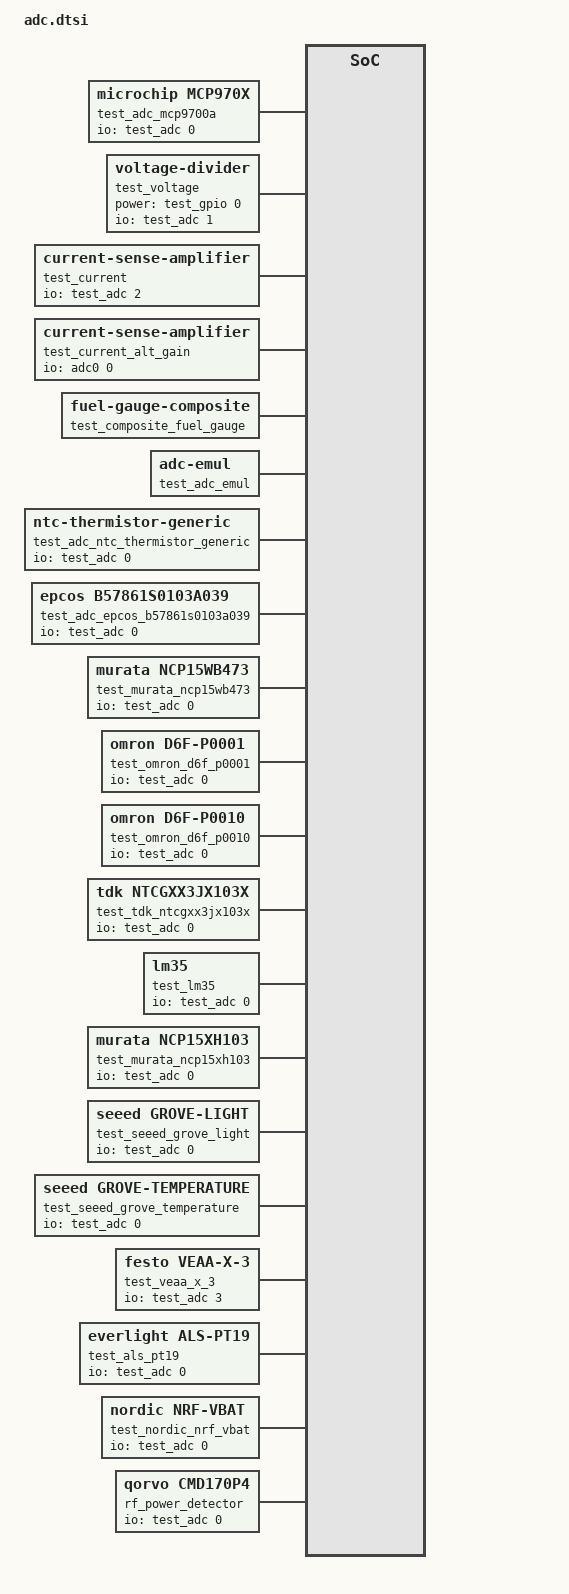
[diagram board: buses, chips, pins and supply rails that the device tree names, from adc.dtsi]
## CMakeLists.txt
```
# SPDX-License-Identifier: Apache-2.0

cmake_minimum_required(VERSION 3.28.0)
find_package(Zephyr REQUIRED HINTS $ENV{ZEPHYR_BASE})
project(build_all)

# Exclude main when running the generic test because ztest supplies its own
target_sources_ifndef(CONFIG_GENERIC_SENSOR_TEST app PRIVATE src/main.c)
target_sources_ifdef(CONFIG_GENERIC_SENSOR_TEST app PRIVATE src/generic_test.c)
```

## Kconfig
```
# Copyright (c) 2023 Google LLC
# SPDX-License-Identifier: Apache-2.0

config GENERIC_SENSOR_TEST
	bool "Compile and run the generic sensor tests"
	depends on ZTEST
	help
	  Enables building and running the generic sensor test suite that will
	  iterate through the device tree and run sample path tests on any
	  sensor that supports the backend sensor emulator API.

config GENERIC_SENSOR_TEST_NUM_EXPECTED_VALS
	int "Number of expected values to use in test"
	default 5
	depends on GENERIC_SENSOR_TEST
	help
	  Controls the number of expected values to use in the generic sensor
	  test, interpolated from the sensor's reported lower and upper sample
	  range boundaries. The test will run one iteration for each expected
	  value. For example, if GENERIC_TEST_NUM_EXPECTED_VALS == 5, and the
	  sensor range is 0..100, the test will run 5 times with expected values
	  0, 25, 50, 75, and 100. These iterations are run in parallel.

source "Kconfig.zephyr"
```

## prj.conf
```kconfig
# zephyr-keep-sorted-start
CONFIG_ADC=y
CONFIG_DAC=y
CONFIG_DHT20_CRC=y
CONFIG_EMUL=y
CONFIG_FUEL_GAUGE=y
CONFIG_GPIO=y
CONFIG_I2C=y
CONFIG_I3C=y
CONFIG_ICM42605_TRIGGER_NONE=y
CONFIG_ICM566XX_TRIGGER_NONE=y
CONFIG_LOG=y
CONFIG_MFD=y
CONFIG_MODBUS=y
CONFIG_MODBUS_RAW_ADU=y
CONFIG_PWM=y
CONFIG_PWM_CAPTURE=y
CONFIG_SENSOR=y
CONFIG_SENSOR_LOG_LEVEL_DBG=y
CONFIG_SERIAL=y
CONFIG_SMBUS=y
CONFIG_SPI=y
CONFIG_SYS_CLOCK_TICKS_PER_SEC=1000
CONFIG_TEST=y
CONFIG_TEST_USERSPACE=y
CONFIG_W1=y
# zephyr-keep-sorted-stop
```

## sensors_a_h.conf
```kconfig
CONFIG_TEST=y
CONFIG_SYS_CLOCK_TICKS_PER_SEC=1000
CONFIG_GPIO=y
CONFIG_I2C=y
CONFIG_SENSOR=y
CONFIG_SPI=y
CONFIG_LOG=y
CONFIG_SENSOR_LOG_LEVEL_DBG=y
CONFIG_TEST_USERSPACE=y
CONFIG_ADC=y
CONFIG_ADT7420=y
CONFIG_ADXL362=y
CONFIG_ADXL372=y
CONFIG_AK8975=y
CONFIG_AMG88XX=y
CONFIG_AMS_IAQ_CORE=y
CONFIG_APDS9960=y
CONFIG_BMA280=y
CONFIG_BMC150_MAGN=y
CONFIG_BME280=y
CONFIG_BMG160=y
CONFIG_BMI160=y
CONFIG_BMI270=y
CONFIG_BMM150=y
CONFIG_BMP388=y
CONFIG_BQ274XX=y
CONFIG_CCS811=y
CONFIG_DHT=y
CONFIG_DPS310=y
CONFIG_ENS210=y
CONFIG_FDC2X1X=y
CONFIG_FXAS21002=y
CONFIG_FXOS8700=y
CONFIG_HMC5883L=y
CONFIG_HP206C=y
CONFIG_HTS221=y
CONFIG_ADXL345=y
CONFIG_MPR=y
```

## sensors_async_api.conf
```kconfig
CONFIG_SENSOR_ASYNC_API=y
CONFIG_ADXL345_STREAM=y
CONFIG_ADXL355_STREAM=y
CONFIG_ADXL362_STREAM=y
CONFIG_ADXL367_STREAM=y
CONFIG_ADXL372_STREAM=y
CONFIG_BMA4XX_STREAM=y
CONFIG_BMM350_STREAM=y
CONFIG_PAA3905_STREAM=y
CONFIG_PAT9136_STREAM=y
CONFIG_RM3100_STREAM=y
CONFIG_IIS3DWB_STREAM=y
CONFIG_LSM6DSV16X_STREAM=y
CONFIG_ICM45686_STREAM=y
CONFIG_ICM4268X_STREAM=y
CONFIG_BMI08X_GYRO_STREAM=y
CONFIG_BMI08X_ACCEL_STREAM=y
CONFIG_MAX30009_STREAM=y
```

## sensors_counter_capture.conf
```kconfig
# Copyright (c) 2026 Meta Platforms
# SPDX-License-Identifier: Apache-2.0

CONFIG_COUNTER_CAPTURE=y
CONFIG_LSM6DSV16X_TRIGGER_GLOBAL_THREAD=y
```

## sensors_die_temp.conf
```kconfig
# zephyr-keep-sorted-start
CONFIG_IIS2ICLX_ENABLE_TEMP=y
CONFIG_IIS3DWB_ENABLE_TEMP=y
CONFIG_ISM330DHCX_ENABLE_TEMP=y
CONFIG_LIS2DE12_ENABLE_TEMP=y
CONFIG_LIS2DS12_ENABLE_TEMP=y
CONFIG_LIS2DUX12_ENABLE_TEMP=y
CONFIG_LSM6DS0_ENABLE_TEMP=y
CONFIG_LSM6DSL_ENABLE_TEMP=y
CONFIG_LSM6DSO16IS_ENABLE_TEMP=y
CONFIG_LSM6DSO_ENABLE_TEMP=y
CONFIG_LSM6DSV16X_ENABLE_TEMP=y
# zephyr-keep-sorted-stop
```

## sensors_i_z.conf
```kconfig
CONFIG_TEST=y
CONFIG_TEST_USERSPACE=y
CONFIG_GPIO=y
CONFIG_I2C=y
CONFIG_SENSOR=y
CONFIG_SPI=y
CONFIG_LOG=y
CONFIG_SENSOR_LOG_LEVEL_DBG=y
CONFIG_ICM42605=y
CONFIG_ICM42605_TRIGGER_OWN_THREAD=y
CONFIG_IIS3DHHC=y
CONFIG_ISL29035=y
CONFIG_LIS2DH=y
CONFIG_LIS2DS12=y
CONFIG_LIS2MDL=y
CONFIG_LIS3MDL=y
CONFIG_LPS22HB=y
CONFIG_LPS22HH=y
CONFIG_LPS25HB=y
CONFIG_LSM303DLHC_MAGN=y
CONFIG_LSM6DS0=y
CONFIG_LSM6DSL=y
CONFIG_LSM6DSO=y
CONFIG_LSM9DS0_GYRO=y
CONFIG_LSM9DS0_MFD=y
CONFIG_MAX30101=y
CONFIG_MAX44009=y
CONFIG_MAX17055=y
CONFIG_MAX1726X=y
CONFIG_MAX6675=y
CONFIG_MCP9808=y
CONFIG_MPU6050=y
CONFIG_MS5607=y
CONFIG_OPT3001=y
CONFIG_SHT3XD=y
CONFIG_SI7006=y
CONFIG_SI7055=y
CONFIG_SI7060=y
CONFIG_SM351LT=y
CONFIG_STM32_TEMP=y
CONFIG_SX9500=y
CONFIG_TACH_NPCX=y
CONFIG_TEMP_NRF5=y
CONFIG_SBS_GAUGE=y
CONFIG_TH02=y
CONFIG_TI_HDC=y
CONFIG_TMP007=y
CONFIG_TMP112=y
CONFIG_TMP116=y
CONFIG_VL53L0X=y
```

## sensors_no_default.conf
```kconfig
# zephyr-keep-sorted-start
CONFIG_BMC150_MAGN_TRIGGER=y
CONFIG_BMC150_MAGN_TRIGGER_DRDY=y
CONFIG_BMM150_TRIGGER_DIRECT=y
CONFIG_BMP388_TRIGGER_DIRECT=y
CONFIG_LM77_TRIGGER=y
CONFIG_LSM9DS0_GYRO_TRIGGERS=y
CONFIG_LSM9DS0_GYRO_TRIGGER_DRDY=y
CONFIG_TMAG5170_TRIGGER_DIRECT=y
CONFIG_VL53L1X_INTERRUPT_MODE=n
CONFIG_VL53L1X_XSHUT=n
# zephyr-keep-sorted-stop
```

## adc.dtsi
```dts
/*
 * Copyright (c) 2023 FTP Technologies
 * Copyright (c) 2023, Google LLC
 *
 * SPDX-License-Identifier: Apache-2.0
 *
 * Application overlay for ADC devices
 */

#include <zephyr/dt-bindings/battery/battery.h>

test_adc_mcp9700a: mcp9700a {
	status = "okay";
	compatible = "microchip,mcp970x";
	family = "MCP9700/9700A";
	io-channels = <&test_adc 0>;
};

test_voltage: voltage {
	status = "okay";
	compatible = "voltage-divider";
	io-channels = <&test_adc 1>;
	io-channel-names = "VOLTAGE";
	output-ohms = <47000>; /* R1 */
	full-ohms = <(100000 + 47000)>; /* R2 + R1 */
	power-gpios = <&test_gpio 0 0>;
};

test_current: current_amp {
	status = "okay";
	compatible = "current-sense-amplifier";
	io-channels = <&test_adc 2>;
	io-channel-names = "CURRENT_AMP";
	sense-resistor-milli-ohms = <1>;
	sense-gain-mult = <1>;
	sense-gain-div = <1>;
	zero-current-voltage-mv = <0>;
};

test_current_alt_gain: current_amp_alt_gain {
	compatible = "current-sense-amplifier";
	io-channels = <&adc0 0>;
	sense-resistor-milli-ohms = <2>;
	sense-gain-mult = <50>;
	gain-extended-range = "ADC_GAIN_1_6";
};

test_composite_fuel_gauge: composite_fuel_gauge {
	compatible = "zephyr,fuel-gauge-composite";
	status = "okay";
	source-primary = <&test_voltage>;
	source-secondary = <&test_current>;
	device-chemistry = "lithium-ion-polymer";
	ocv-capacity-table-0 = <BATTERY_OCV_CURVE_LITHIUM_ION_POLYMER_DEFAULT>;
	charge-full-design-microamp-hours = <1000000>;
};

test_adc_emul: adc-emul {
	compatible = "zephyr,adc-emul";
	nchannels = <2>;
	ref-internal-mv = <3300>;
	ref-external1-mv = <5000>;
	#io-channel-cells = <1>;
	status = "okay";
};

test_adc_ntc_thermistor_generic: ntc-thermistor-generic {
	compatible = "ntc-thermistor-generic";
	io-channels = <&test_adc 0>;
	pullup-uv = <3300000>;
	pullup-ohm = <0>;
	pulldown-ohm = <10000>;
	connected-positive;
	zephyr,compensation-table = <0 0>, <1 1>;
};

test_adc_epcos_b57861s0103a039: epcos-b57861s0103a039 {
	compatible = "epcos,b57861s0103a039";
	io-channels = <&test_adc 0>;
	pullup-uv = <3300000>;
	pullup-ohm = <0>;
	pulldown-ohm = <10000>;
	connected-positive;
};

test_murata_ncp15wb473: murata-ncp15wb473 {
	compatible = "murata,ncp15wb473";
	io-channels = <&test_adc 0>;
	pullup-uv = <3300000>;
	pullup-ohm = <0>;
	pulldown-ohm = <10000>;
	connected-positive;
};

test_omron_d6f_p0001: test-omron-d6f-p0001 {
	status = "okay";
	compatible = "omron,d6f-p0001";
	io-channels = <&test_adc 0>;
};

test_omron_d6f_p0010: test-omron-d6f-p0010 {
	status = "okay";
	compatible = "omron,d6f-p0010";
	io-channels = <&test_adc 0>;
};

test_tdk_ntcgxx3jx103x: tdk-ntcgxx3jx103x {
	compatible = "tdk,ntcgxx3jx103x";
	io-channels = <&test_adc 0>;
	pullup-uv = <3300000>;
	pullup-ohm = <0>;
	pulldown-ohm = <10000>;
	connected-positive;
};

test_lm35: lm35 {
	compatible = "lm35";
	io-channels = <&test_adc 0>;
	status = "okay";
};

test_murata_ncp15xh103: murata-ncp15xh103 {
	compatible = "murata,ncp15xh103";
	io-channels = <&test_adc 0>;
	pullup-uv = <3300000>;
	pullup-ohm = <0>;
	pulldown-ohm = <10000>;
	connected-positive;
};

test_seeed_grove_light: seeed-grove-light {
	compatible = "seeed,grove-light";
	io-channels = <&test_adc 0>;
};

test_seeed_grove_temperature: seeed-grove-temperature {
	compatible = "seeed,grove-temperature";
	io-channels = <&test_adc 0>;
};

test_veaa_x_3: test_veaa_x_3 {
	status = "okay";
	compatible = "festo,veaa-x-3";
	io-channels = <&test_adc 3>;
	dac = <&test_dac>;
	dac-channel-id = <2>;
	dac-resolution = <12>;
	pressure-range-type = "D2";
};

test_als_pt19: test_als-pt19 {
	compatible = "everlight,als-pt19";
	io-channels = <&test_adc 0>;
	load-resistor = <10000>;
};

test_nordic_nrf_vbat: test_nordic_nrf_vbat {
	status = "okay";
	compatible = "nordic,nrf-vbat";
	io-channels = <&test_adc 0>;
	invert-voltage;
};

rf_power_detector: rf-power-detector {
	compatible = "qorvo,cmd170p4";
	io-channels = <&test_adc 0>;
};
```

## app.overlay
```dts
/*
 * Copyright (c) 2020, Linaro Ltd.
 *
 * SPDX-License-Identifier: Apache-2.0
 *
 * Application overlay for testing driver builds
 *
 * Names in this file should be chosen in a way that won't conflict
 * with real-world devicetree nodes, to allow these tests to run on
 * (and be extended to test) real hardware.
 */

/ {
	test {
		#address-cells = <1>;
		#size-cells = <1>;

		test_adc: adc@adc0adc0 {
			compatible = "vnd,adc";
			reg = <0xadc0adc0 0x1000>;
			#io-channel-cells = <1>;
			#address-cells = <1>;
			#size-cells = <0>;
			status = "okay";

			channel@0 {
				reg = <0>;
				zephyr,gain = "ADC_GAIN_1";
				zephyr,reference = "ADC_REF_VDD_1";
				zephyr,acquisition-time = <ADC_ACQ_TIME_DEFAULT>;
				zephyr,input-positive = <0>;
				zephyr,resolution = <12>;
			};

			channel@1 {
				reg = <1>;
				zephyr,gain = "ADC_GAIN_1_6";
				zephyr,reference = "ADC_REF_INTERNAL";
				zephyr,acquisition-time = <ADC_ACQ_TIME_DEFAULT>;
				zephyr,input-positive = <0>;
				zephyr,resolution = <12>;
			};

			channel@2 {
				reg = <2>;
				zephyr,gain = "ADC_GAIN_1_6";
				zephyr,reference = "ADC_REF_INTERNAL";
				zephyr,acquisition-time = <ADC_ACQ_TIME_DEFAULT>;
				zephyr,input-positive = <0>;
				zephyr,resolution = <12>;
			};

#include "adc.dtsi"
		};

		test_dac: dac@dac0dac0 {
			compatible = "vnd,dac";
			reg = <0xdac0dac0 0x1000>;
			#io-channel-cells = <1>;
			status = "okay";
		};

		test_gpio: gpio@deadbeef {
			compatible = "vnd,gpio";
			reg = <0xdeadbeef 0x1000>;
			gpio-controller;
			#gpio-cells = <0x2>;
			status = "okay";

#include "gpio.dtsi"
		};

		test_i2c: i2c@11112222 {
			compatible = "zephyr,i2c-emul-controller";
			reg = <0x11112222 0x1000>;
			#address-cells = <1>;
			#size-cells = <0>;
			clock-frequency = <100000>;
			status = "okay";

#include "i2c.dtsi"
		};

		test_pwm: pwm@12341234 {
			compatible = "vnd,pwm";
			reg = <0x12341234 0x1000>;
			#pwm-cells = <3>;
			status = "okay";

#include "pwm.dtsi"
		};

		test_spi: spi@33334444 {
			compatible = "zephyr,spi-emul-controller";
			reg = <0x33334444 0x1000>;
			#address-cells = <1>;
			#size-cells = <0>;
			clock-frequency = <2000000>;

			/* one entry for every devices at spi.dtsi */
			cs-gpios = <&test_gpio 0 0>,	/* 0x00 */
				   <&test_gpio 0 0>,
				   <&test_gpio 0 0>,
				   <&test_gpio 0 0>,
				   <&test_gpio 0 0>,
				   <&test_gpio 0 0>,
				   <&test_gpio 0 0>,
				   <&test_gpio 0 0>,
				   <&test_gpio 0 0>,
				   <&test_gpio 0 0>,
				   <&test_gpio 0 0>,
				   <&test_gpio 0 0>,
				   <&test_gpio 0 0>,
				   <&test_gpio 0 0>,
				   <&test_gpio 0 0>,
				   <&test_gpio 0 0>,
				   <&test_gpio 0 0>,	/* 0x10 */
				   <&test_gpio 0 0>,
				   <&test_gpio 0 0>,
				   <&test_gpio 0 0>,
				   <&test_gpio 0 0>,
				   <&test_gpio 0 0>,
				   <&test_gpio 0 0>,
				   <&test_gpio 0 0>,
				   <&test_gpio 0 0>,
				   <&test_gpio 0 0>,
				   <&test_gpio 0 0>,
				   <&test_gpio 0 0>,
				   <&test_gpio 0 0>,
				   <&test_gpio 0 0>,
				   <&test_gpio 0 0>,
				   <&test_gpio 0 0>,
				   <&test_gpio 0 0>,	/* 0x20 */
				   <&test_gpio 0 0>,
				   <&test_gpio 0 0>,
				   <&test_gpio 0 0>,
				   <&test_gpio 0 0>,
				   <&test_gpio 0 0>,
				   <&test_gpio 0 0>,
				   <&test_gpio 0 0>,
				   <&test_gpio 0 0>,
				   <&test_gpio 0 0>,
				   <&test_gpio 0 0>,
				   <&test_gpio 0 0>,
				   <&test_gpio 0 0>,
				   <&test_gpio 0 0>,
				   <&test_gpio 0 0>,
				   <&test_gpio 0 0>,
				   <&test_gpio 0 0>,	/* 0x30 */
				   <&test_gpio 0 0>,
				   <&test_gpio 0 0>,
				   <&test_gpio 0 0>,
				   <&test_gpio 0 0>,
				   <&test_gpio 0 0>,
				   <&test_gpio 0 0>,
				   <&test_gpio 0 0>,
				   <&test_gpio 0 0>,
				   <&test_gpio 0 0>,
				   <&test_gpio 0 0>,
				   <&test_gpio 0 0>,
				   <&test_gpio 0 0>,
				   <&test_gpio 0 0>,	/* 0x3D */
				   <&test_gpio 0 0>,
				   <&test_gpio 0 0>,
				   <&test_gpio 0 0>,
				   <&test_gpio 0 0>,
				   <&test_gpio 0 0>,
				   <&test_gpio 0 0>,
				   <&test_gpio 0 0>,
				   <&test_gpio 0 0>,
				   <&test_gpio 0 0>;	/* 0x46 */
			status = "okay";
#include "spi.dtsi"
		};

		test_uart: uart@55556666 {
			compatible = "vnd,serial";
			reg = <0x55556666 0x1000>;
			status = "okay";

#include "uart.dtsi"
		};

		test_w1: w1@66660000 {
			compatible = "vnd,w1";
			reg = <0x66660000 0x1000>;
			#address-cells = <1>;
			#size-cells = <0>;
			status = "okay";

#include "w1.dtsi"
		};

		test_i3c: i3c@f0cacc1a {
			compatible = "vnd,i3c";
			reg = <0xf0cacc1a 0x1000>;
			#address-cells = <3>;
			#size-cells = <0>;
			status = "okay";

#include "i3c.dtsi"
		};

		native_linux_temp {
			compatible = "zephyr,native-linux-temp";
			path = "/tmp/native-linux-temp";
		};
	};
};

/* Put device specific modifications to properties or disabling of devices
 * here to keep the bus specific dtsi files (i2c.dtsi, spi.dtsi, etc..)
 * pristine
 */

/* disable device to conflict with i2c version */
&test_i2c_ism330dhcx {
	status = "disabled";
};

/* disable device to conflict with i2c version */
&test_spi_bme280 {
	status = "disabled";
};

/* disable device to conflict with i2c version */
&test_spi_iis2dh {
	status = "disabled";
};
```

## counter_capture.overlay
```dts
/*
 * Copyright (c) 2026 Meta Platforms
 *
 * SPDX-License-Identifier: Apache-2.0
 *
 * Application overlay for testing counter-capture trigger builds
 */

#include <zephyr/dt-bindings/sensor/lsm6dsv16x.h>

/ {
	test {
		test_counter: counter@cafecafe {
			compatible = "vnd,counter";
			reg = <0xcafecafe 0x1000>;
			#counter-capture-cells = <2>;
			status = "okay";
		};
	};
};

&test_i2c {
	test_i2c_lsm6dsv16x_counter_capture: lsm6dsv16x@ca {
		compatible = "st,lsm6dsv16x";
		reg = <0xca>;
		int1-counter-capture = <&test_counter 0 0>;
		accel-range = <LSM6DSV16X_DT_FS_8G>;
		accel-odr = <LSM6DSVXXX_DT_ODR_AT_60Hz>;
		gyro-range = <LSM6DSV16X_DT_FS_2000DPS>;
		gyro-odr = <LSM6DSVXXX_DT_ODR_AT_60Hz>;
	};
};
```

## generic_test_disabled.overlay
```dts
/*
 * Copyright The Zephyr Project Contributors
 * SPDX-License-Identifier: Apache-2.0
 */

&test_i2c_vl53l5cx {
	status = "disabled";
};
```

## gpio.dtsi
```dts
/*
 * Copyright (c) 2020, Laird Connectivity
 *
 * SPDX-License-Identifier: Apache-2.0
 *
 * Application overlay for gpio devices
 */

test_gpio_sm351lt: sm351lt0 {
	compatible = "honeywell,sm351lt";
	gpios = <&test_gpio 0 0>;
};

test_gpio_dht22: dht22 {
	compatible = "aosong,dht";
	status = "okay";
	dio-gpios = <&test_gpio 0 0>;
	/* dht22; */
};

test_gpio_hcsr04: hcsr04 {
	compatible = "hc-sr04";
	trigger-gpios = <&test_gpio 0 0>;
	echo-gpios = <&test_gpio 1 0>;
};

test_gpio_tach_gpio: tach-gpio {
	compatible = "zephyr,tach-gpio";
	gpios = <&test_gpio 0 0>;
	pulses-per-round = <1>;
};

test_gpio_s9706: s9706 {
	compatible = "hamamatsu,s9706";
	range-gpios = <&test_gpio 0 0>;
	gate-gpios = <&test_gpio 1 0>;
	clk-gpios = <&test_gpio 2 0>;
	data-gpios = <&test_gpio 3 0>;
	max-frequency = <1500000>;
	integration-time = <5000>;
};
```

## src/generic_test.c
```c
/*
 * Copyright (c) 2023 Google LLC
 * SPDX-License-Identifier: Apache-2.0
 */

#include <zephyr/device.h>
#include <zephyr/drivers/emul_sensor.h>
#include <zephyr/drivers/emul.h>
#include <zephyr/ztest.h>
#include <zephyr/drivers/sensor.h>
#include <zephyr/drivers/sensor_data_types.h>
#include <zephyr/rtio/rtio.h>
#include <zephyr/sys/bitarray.h>

#include <zephyr/logging/log.h>
LOG_MODULE_REGISTER(generic_test);

/**
 * A union of all sensor data types.
 */
union sensor_data_union {
	struct sensor_three_axis_data three_axis;
	struct sensor_occurrence_data occurrence;
	struct sensor_q31_data q31;
	struct sensor_byte_data byte;
	struct sensor_uint64_data uint64;
};

/*
 * Set up an RTIO context that can be shared for all sensors
 */

static struct sensor_chan_spec iodev_all_channels[SENSOR_CHAN_ALL];
static struct sensor_read_config iodev_read_config = {
	.channels = iodev_all_channels,
	.max = SENSOR_CHAN_ALL,
};
RTIO_IODEV_DEFINE(iodev_read, &__sensor_iodev_api, &iodev_read_config);

/* Create the RTIO context to service the reading */
RTIO_DEFINE_WITH_MEMPOOL(sensor_read_rtio_ctx, 1, 1, 1, 64, 4);

/**
 * @brief Prepare the RTIO context for next test
 */
static void before(void *args)
{
	ARG_UNUSED(args);

	/* Clear the array of requested channels */
	memset(iodev_all_channels, 0, sizeof(iodev_all_channels));

	/* Reset the channel count */
	iodev_read_config.count = 0;

	/* Remove previous sensor pointer */
	iodev_read_config.sensor = NULL;

	/* Wipe the mempool by marking every block free */
	zassert_ok(sys_bitarray_clear_region(sensor_read_rtio_ctx.block_pool->bitmap,
					     sensor_read_rtio_ctx.block_pool->info.num_blocks,
					     0));

	/* Flush the SQ and CQ */
	rtio_sqe_drop_all(&sensor_read_rtio_ctx);
	while (rtio_cqe_consume(&sensor_read_rtio_ctx)) {
		;
	}
}

/**
 * @brief Helper function the carries out the generic sensor test for a given sensor device.
 *        Verifies that the device has a suitable emulator that implements the backend API and
 *        skips the test gracefully if not.
 */
static void run_generic_test(const struct device *dev)
{
	zassert_not_null(dev, "Cannot get device pointer. Is this driver properly instantiated?");

	const struct emul *emul = emul_get_binding(dev->name);

	/* Skip this sensor if there is no emulator loaded. */
	if (!emul) {
		ztest_test_skip();
	}

	/* Also skip if this emulator does not implement the backend API. */
	if (!emul_sensor_backend_is_supported(emul)) {
		ztest_test_skip();
	}

	/*
	 * Begin the actual test sequence
	 */

	static struct {
		bool supported;
		bool received;
		q31_t expected_values[CONFIG_GENERIC_SENSOR_TEST_NUM_EXPECTED_VALS];
		q31_t epsilon;
		int8_t expected_value_shift;
	} channel_table[SENSOR_CHAN_ALL];

	memset(channel_table, 0, sizeof(channel_table));

	/* Discover supported channels on this device and fill out our sensor read request */
	for (enum sensor_channel ch = 0; ch < ARRAY_SIZE(channel_table); ch++) {
		if (SENSOR_CHANNEL_3_AXIS(ch)) {
			continue;
		}

		q31_t lower, upper;
		int8_t shift;
		struct sensor_chan_spec ch_spec = {.chan_type = ch, .chan_idx = 0};

		if (emul_sensor_backend_get_sample_range(emul, ch_spec, &lower, &upper,
							 &channel_table[ch].epsilon, &shift) == 0) {
			/* This channel is supported */
			channel_table[ch].supported = true;

			LOG_INF("CH %d: lower=%d, upper=%d, eps=%d, shift=%d", ch, lower, upper,
				channel_table[ch].epsilon, shift);

			/* Add to the list of channels to read */
			iodev_all_channels[iodev_read_config.count++].chan_type = ch;

			/* Generate a set of CONFIG_GENERIC_SENSOR_TEST_NUM_EXPECTED_VALS test
			 * values.
			 */

			channel_table[ch].expected_value_shift = shift;
			for (size_t i = 0; i < CONFIG_GENERIC_SENSOR_TEST_NUM_EXPECTED_VALS; i++) {
				channel_table[ch].expected_values[i] =
					lower +
					(i * ((int64_t)upper - lower) /
					 (CONFIG_GENERIC_SENSOR_TEST_NUM_EXPECTED_VALS - 1));
				LOG_INF("CH %d: Expected value %d/%d: %d", ch, i + 1,
					CONFIG_GENERIC_SENSOR_TEST_NUM_EXPECTED_VALS,
					channel_table[ch].expected_values[i]);
			}
		}
	}
	iodev_read_config.sensor = dev;

	/* Do a read of all channels for quantity CONFIG_GENERIC_SENSOR_TEST_NUM_EXPECTED_VALS
	 * iterations.
	 */

	for (size_t iteration = 0; iteration < CONFIG_GENERIC_SENSOR_TEST_NUM_EXPECTED_VALS;
	     iteration++) {
		int rv;

		/* Reset received flag */
		for (size_t i = 0; i < ARRAY_SIZE(channel_table); i++) {
			channel_table[i].received = false;
		}

		/* Set this iteration's expected values in emul for every supported channel */
		for (size_t i = 0; i < iodev_read_config.count; i++) {
			struct sensor_chan_spec ch_spec = iodev_all_channels[i];

			rv = emul_sensor_backend_set_channel(
				emul, ch_spec,
				&channel_table[ch_spec.chan_type].expected_values[iteration],
				channel_table[ch_spec.chan_type].expected_value_shift);
			zassert_ok(rv,
				   "Cannot set value 0x%08x on channel (type: %d, index: %d) "
				   "(error %d, iteration %d/%d)",
				   channel_table[i].expected_values[iteration], ch_spec.chan_type,
				   ch_spec.chan_idx, rv, iteration + 1,
				   CONFIG_GENERIC_SENSOR_TEST_NUM_EXPECTED_VALS);
		}

		/* Perform the actual sensor read */
		rv = sensor_read_async_mempool(&iodev_read, &sensor_read_rtio_ctx, NULL);
		zassert_ok(rv, "Could not read sensor (error %d, iteration %d/%d)", rv,
			   iteration + 1, CONFIG_GENERIC_SENSOR_TEST_NUM_EXPECTED_VALS);

		/* Wait for a CQE */
		struct rtio_cqe *cqe = rtio_cqe_consume_block(&sensor_read_rtio_ctx);

		zassert_ok(cqe->result, "CQE has failed status (error %d, iteration %d/%d)",
			   cqe->result, iteration + 1,
			   CONFIG_GENERIC_SENSOR_TEST_NUM_EXPECTED_VALS);

		uint8_t *buf = NULL;
		uint32_t buf_len = 0;

		/* Cache the data from the CQE */
		rtio_cqe_get_mempool_buffer(&sensor_read_rtio_ctx, cqe, &buf, &buf_len);

		/* Release the CQE */
		rtio_cqe_release(&sensor_read_rtio_ctx, cqe);

		const struct sensor_decoder_api *decoder;
		union sensor_data_union decoded_data;

		zassert_ok(sensor_get_decoder(dev, &decoder));

		/* Loop through each channel */
		for (int ch = 0; ch < ARRAY_SIZE(channel_table); ch++) {
			if (!channel_table[ch].supported) {
				continue;
			}

			struct sensor_decode_context ctx =
				SENSOR_DECODE_CONTEXT_INIT(decoder, buf, ch, 0);

			rv = sensor_decode(&ctx, &decoded_data, 1);
			zassert_equal(1, rv, "Could not decode (error %d, ch %d, iteration %d/%d)",
				      rv, ch, iteration + 1,
				      CONFIG_GENERIC_SENSOR_TEST_NUM_EXPECTED_VALS);

			channel_table[ch].received = true;

			/* Retrieve the actual value */
			q31_t q;
			int8_t shift;

			q = decoded_data.q31.readings[0].value;
			shift = decoded_data.q31.shift;

			/* Align everything to be a 64-bit Q32.32 number for comparison */
			int64_t expected_shifted =
				(int64_t)channel_table[ch].expected_values[iteration]
				<< channel_table[ch].expected_value_shift;
			int64_t actual_shifted = (int64_t)q << shift;
			int64_t epsilon_shifted = (int64_t)channel_table[ch].epsilon
						  << channel_table[ch].expected_value_shift;

			zassert_within(expected_shifted, actual_shifted, epsilon_shifted,
				       "Expected %lld, got %lld (shift %d, ch %d, iteration %d/%d, "
				       "Error %lld, Epsilon %lld)",
				       expected_shifted, actual_shifted, shift, ch, iteration + 1,
				       CONFIG_GENERIC_SENSOR_TEST_NUM_EXPECTED_VALS,
				       expected_shifted - actual_shifted, epsilon_shifted);
		}

		/* Release the memory */
		rtio_release_buffer(&sensor_read_rtio_ctx, buf, buf_len);

		/* Ensure all supported channels were received */
		int missing_channel_count = 0;

		for (size_t i = 0; i < ARRAY_SIZE(channel_table); i++) {
			if (channel_table[i].supported && !channel_table[i].received) {
				missing_channel_count++;
			}
		}

		zassert_equal(0, missing_channel_count, "%d channel(s) not received",
			      missing_channel_count);
	}
}

#define DECLARE_ZTEST_PER_DEVICE(n)                                                                \
	ZTEST(generic, test_##n)                                                                   \
	{                                                                                          \
		run_generic_test(DEVICE_DT_GET(n));                                                \
	}

/* Iterate through each of the emulated buses and create a test for each device. */
DT_FOREACH_CHILD_STATUS_OKAY(DT_NODELABEL(test_i2c0), DECLARE_ZTEST_PER_DEVICE)
DT_FOREACH_CHILD_STATUS_OKAY(DT_NODELABEL(test_i2c1), DECLARE_ZTEST_PER_DEVICE)
DT_FOREACH_CHILD_STATUS_OKAY(DT_NODELABEL(test_i3c), DECLARE_ZTEST_PER_DEVICE)
DT_FOREACH_CHILD_STATUS_OKAY(DT_NODELABEL(test_spi), DECLARE_ZTEST_PER_DEVICE)

ZTEST_SUITE(generic, NULL, NULL, before, NULL, NULL);
```
